AUTOSAR XML (schema 4-2-1)
package /MICROSAR/ComM_swc
  mode declaration group ComMMode: initial-mode=COMM_NO_COMMUNICATION
    mode COMM_NO_COMMUNICATION
    mode COMM_SILENT_COMMUNICATION
    mode COMM_FULL_COMMUNICATION
  data type mapping set ComMMode_DataTypeMappingSet: mode-request-type-map{implementation-data-type=ComM_ModeType, mode-group=ComMMode}  # Data Mapping for the Mode Declaration Group ComMMode.
package /MICROSAR/ComM_swc/DataTypes
  4 x impl type, all with category=TYPE_REFERENCE, implementation-data-type=uint8:
    ComM_ModeType: compu {0=COMM_NO_COMMUNICATION, 1=COMM_SILENT_COMMUNICATION, 2=COMM_FULL_COMMUNICATION}, range raw 0..3
    ComM_InhibitionStatusType: range raw 0..255
    ComM_UserHandleType: range raw 0..255
    NetworkHandleType: range raw 0..255, type-emitter=ComM
package /MICROSAR/ComM_swc/Interfaces
  4 x client server interface, all with is-service=true, service-kind=COM-MANAGER:
    ComM_UserRequest
      4 x operation:
        RequestComMode: possible-error=[ComM_UserRequest/E_NOT_OK, E_MODE_LIMITATION]
          arg ComMode: type=ComM_ModeType, direction=IN
        GetCurrentComMode: possible-error=ComM_UserRequest/E_NOT_OK
          arg ComMode: type=ComM_ModeType, direction=OUT
        GetMaxComMode: possible-error=ComM_UserRequest/E_NOT_OK
          arg ComMode: type=ComM_ModeType, direction=OUT
        GetRequestedComMode: possible-error=ComM_UserRequest/E_NOT_OK
          arg ComMode: type=ComM_ModeType, direction=OUT
      error E_NOT_OK: error-code=1
      error E_MODE_LIMITATION: error-code=2
    ComM_ECUModeLimitation
      4 x operation, all with possible-error=ComM_ECUModeLimitation/E_NOT_OK:
        LimitECUToNoComMode
          arg Status: type=boolean, direction=IN
        ReadInhibitCounter
          arg CounterValue: type=uint16, direction=OUT
        ResetInhibitCounter
        SetECUGroupClassification
          arg Status: type=ComM_InhibitionStatusType, direction=IN
      error E_NOT_OK: error-code=1
    ComM_ChannelWakeUp
      operation PreventWakeUp: possible-error=ComM_ChannelWakeUp/E_NOT_OK
        arg Status: type=boolean, direction=IN
      operation GetInhibitionStatus: possible-error=ComM_ChannelWakeUp/E_NOT_OK
        arg Status: type=ComM_InhibitionStatusType, direction=OUT
      error E_NOT_OK: error-code=1
    ComM_ChannelLimitation
      operation LimitChannelToNoComMode: possible-error=ComM_ChannelLimitation/E_NOT_OK
        arg Status: type=boolean, direction=IN
      operation GetInhibitionStatus: possible-error=ComM_ChannelLimitation/E_NOT_OK
        arg Status: type=ComM_InhibitionStatusType, direction=OUT
      error E_NOT_OK: error-code=1
  mode switch interface ComM_CurrentMode: is-service=true, service-kind=COM-MANAGER
    mode group currentMode: type=ComMMode
package /MICROSAR/ComM_swc/ComponentTypes
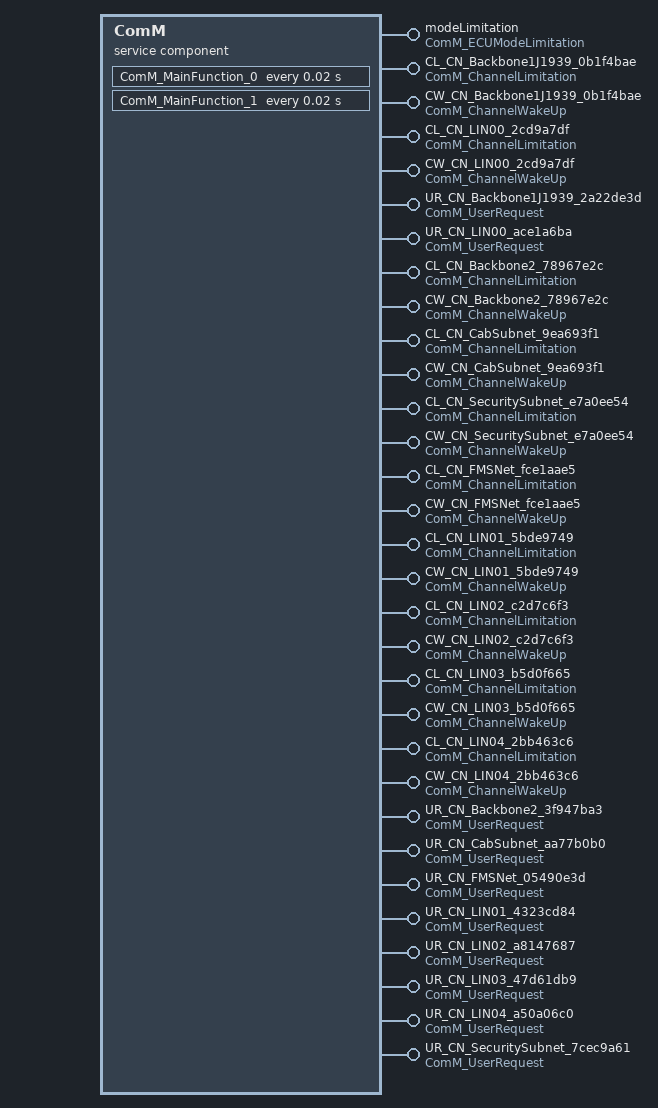
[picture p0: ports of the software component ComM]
  service sw component type ComM: category=SERVICE_COMPONENT
    31 x provide port:
      modeLimitation: provided-interface=ComM_ECUModeLimitation
      CL_CN_Backbone1J1939_0b1f4bae: provided-interface=ComM_ChannelLimitation
      CW_CN_Backbone1J1939_0b1f4bae: provided-interface=ComM_ChannelWakeUp
      CL_CN_LIN00_2cd9a7df: provided-interface=ComM_ChannelLimitation
      CW_CN_LIN00_2cd9a7df: provided-interface=ComM_ChannelWakeUp
      UR_CN_Backbone1J1939_2a22de3d: provided-interface=ComM_UserRequest
      UR_CN_LIN00_ace1a6ba: provided-interface=ComM_UserRequest
      CL_CN_Backbone2_78967e2c: provided-interface=ComM_ChannelLimitation
      CW_CN_Backbone2_78967e2c: provided-interface=ComM_ChannelWakeUp
      CL_CN_CabSubnet_9ea693f1: provided-interface=ComM_ChannelLimitation
      CW_CN_CabSubnet_9ea693f1: provided-interface=ComM_ChannelWakeUp
      CL_CN_SecuritySubnet_e7a0ee54: provided-interface=ComM_ChannelLimitation
      CW_CN_SecuritySubnet_e7a0ee54: provided-interface=ComM_ChannelWakeUp
      CL_CN_FMSNet_fce1aae5: provided-interface=ComM_ChannelLimitation
      CW_CN_FMSNet_fce1aae5: provided-interface=ComM_ChannelWakeUp
      CL_CN_LIN01_5bde9749: provided-interface=ComM_ChannelLimitation
      CW_CN_LIN01_5bde9749: provided-interface=ComM_ChannelWakeUp
      CL_CN_LIN02_c2d7c6f3: provided-interface=ComM_ChannelLimitation
      CW_CN_LIN02_c2d7c6f3: provided-interface=ComM_ChannelWakeUp
      CL_CN_LIN03_b5d0f665: provided-interface=ComM_ChannelLimitation
      CW_CN_LIN03_b5d0f665: provided-interface=ComM_ChannelWakeUp
      CL_CN_LIN04_2bb463c6: provided-interface=ComM_ChannelLimitation
      CW_CN_LIN04_2bb463c6: provided-interface=ComM_ChannelWakeUp
      UR_CN_Backbone2_3f947ba3: provided-interface=ComM_UserRequest
      UR_CN_CabSubnet_aa77b0b0: provided-interface=ComM_UserRequest
      UR_CN_FMSNet_05490e3d: provided-interface=ComM_UserRequest
      UR_CN_LIN01_4323cd84: provided-interface=ComM_UserRequest
      UR_CN_LIN02_a8147687: provided-interface=ComM_UserRequest
      UR_CN_LIN03_47d61db9: provided-interface=ComM_UserRequest
      UR_CN_LIN04_a50a06c0: provided-interface=ComM_UserRequest
      UR_CN_SecuritySubnet_7cec9a61: provided-interface=ComM_UserRequest
    behavior ComMInternalBehavior: data-type-mapping=ComMMode_DataTypeMappingSet, handle-termination-and-restart=NO-SUPPORT, included-data-type-set=data-type=[ComM_ModeType, ComM_InhibitionStatusType, ComM_UserHandleType, NetworkHandleType]
      timing event Timer_ComM_MainFunction_0: start-on-event=ComM_MainFunction_0, period=0.02
      timing event Timer_ComM_MainFunction_1: start-on-event=ComM_MainFunction_1, period=0.02
      20 x operation invoked event:
        OpEventGetInhibitionStatus_GetInhibitionStatus_CL_CN_Backbone1J1939_0b1f4bae: start-on-event=GetInhibitionStatus, operation=CL_CN_Backbone1J1939_0b1f4bae.GetInhibitionStatus
        OpEventGetInhibitionStatus_GetInhibitionStatus_CW_CN_Backbone1J1939_0b1f4bae: start-on-event=GetInhibitionStatus, operation=CW_CN_Backbone1J1939_0b1f4bae.GetInhibitionStatus
        OpEventGetInhibitionStatus_GetInhibitionStatus_CL_CN_LIN00_2cd9a7df: start-on-event=GetInhibitionStatus, operation=CL_CN_LIN00_2cd9a7df.GetInhibitionStatus
        OpEventGetInhibitionStatus_GetInhibitionStatus_CW_CN_LIN00_2cd9a7df: start-on-event=GetInhibitionStatus, operation=CW_CN_LIN00_2cd9a7df.GetInhibitionStatus
        OpEventLimitECUToNoComMode_LimitECUToNoComMode_modeLimitation: start-on-event=LimitECUToNoComMode, operation=modeLimitation.LimitECUToNoComMode
        OpEventReadInhibitCounter_ReadInhibitCounter_modeLimitation: start-on-event=ReadInhibitCounter, operation=modeLimitation.ReadInhibitCounter
        OpEventResetInhibitCounter_ResetInhibitCounter_modeLimitation: start-on-event=ResetInhibitCounter, operation=modeLimitation.ResetInhibitCounter
        OpEventSetECUGroupClassification_SetECUGroupClassification_modeLimitation: start-on-event=SetECUGroupClassification, operation=modeLimitation.SetECUGroupClassification
        OpEventLimitChannelToNoComMode_LimitChannelToNoComMode_CL_CN_Backbone1J1939_0b1f4bae: start-on-event=LimitChannelToNoComMode, operation=CL_CN_Backbone1J1939_0b1f4bae.LimitChannelToNoComMode
        OpEventLimitChannelToNoComMode_LimitChannelToNoComMode_CL_CN_LIN00_2cd9a7df: start-on-event=LimitChannelToNoComMode, operation=CL_CN_LIN00_2cd9a7df.LimitChannelToNoComMode
        OpEventPreventWakeUp_PreventWakeUp_CW_CN_Backbone1J1939_0b1f4bae: start-on-event=PreventWakeUp, operation=CW_CN_Backbone1J1939_0b1f4bae.PreventWakeUp
        OpEventPreventWakeUp_PreventWakeUp_CW_CN_LIN00_2cd9a7df: start-on-event=PreventWakeUp, operation=CW_CN_LIN00_2cd9a7df.PreventWakeUp
        OpEventRequestComMode_RequestComMode_UR_CN_Backbone1J1939_2a22de3d: start-on-event=RequestComMode, operation=UR_CN_Backbone1J1939_2a22de3d.RequestComMode
        OpEventRequestComMode_RequestComMode_UR_CN_LIN00_ace1a6ba: start-on-event=RequestComMode, operation=UR_CN_LIN00_ace1a6ba.RequestComMode
        OpEventGetCurrentComMode_GetCurrentComMode_UR_CN_Backbone1J1939_2a22de3d: start-on-event=GetCurrentComMode, operation=UR_CN_Backbone1J1939_2a22de3d.GetCurrentComMode
        OpEventGetCurrentComMode_GetCurrentComMode_UR_CN_LIN00_ace1a6ba: start-on-event=GetCurrentComMode, operation=UR_CN_LIN00_ace1a6ba.GetCurrentComMode
        OpEventGetMaxComMode_GetMaxComMode_UR_CN_Backbone1J1939_2a22de3d: start-on-event=GetMaxComMode, operation=UR_CN_Backbone1J1939_2a22de3d.GetMaxComMode
        OpEventGetMaxComMode_GetMaxComMode_UR_CN_LIN00_ace1a6ba: start-on-event=GetMaxComMode, operation=UR_CN_LIN00_ace1a6ba.GetMaxComMode
        OpEventGetRequestedComMode_GetRequestedComMode_UR_CN_Backbone1J1939_2a22de3d: start-on-event=GetRequestedComMode, operation=UR_CN_Backbone1J1939_2a22de3d.GetRequestedComMode
        OpEventGetRequestedComMode_GetRequestedComMode_UR_CN_LIN00_ace1a6ba: start-on-event=GetRequestedComMode, operation=UR_CN_LIN00_ace1a6ba.GetRequestedComMode
      8 x timing event, all with period=0.02:
        Timer_ComM_MainFunction_{2..9}: start-on-event=ComM_MainFunction_{2..9}
      64 x operation invoked event:
        OpEventGetInhibitionStatus_GetInhibitionStatus_CL_CN_Backbone2_78967e2c: start-on-event=GetInhibitionStatus, operation=CL_CN_Backbone2_78967e2c.GetInhibitionStatus
        OpEventGetInhibitionStatus_GetInhibitionStatus_CW_CN_Backbone2_78967e2c: start-on-event=GetInhibitionStatus, operation=CW_CN_Backbone2_78967e2c.GetInhibitionStatus
        OpEventGetInhibitionStatus_GetInhibitionStatus_CL_CN_CabSubnet_9ea693f1: start-on-event=GetInhibitionStatus, operation=CL_CN_CabSubnet_9ea693f1.GetInhibitionStatus
        OpEventGetInhibitionStatus_GetInhibitionStatus_CW_CN_CabSubnet_9ea693f1: start-on-event=GetInhibitionStatus, operation=CW_CN_CabSubnet_9ea693f1.GetInhibitionStatus
        OpEventGetInhibitionStatus_GetInhibitionStatus_CL_CN_SecuritySubnet_e7a0ee54: start-on-event=GetInhibitionStatus, operation=CL_CN_SecuritySubnet_e7a0ee54.GetInhibitionStatus
        OpEventGetInhibitionStatus_GetInhibitionStatus_CW_CN_SecuritySubnet_e7a0ee54: start-on-event=GetInhibitionStatus, operation=CW_CN_SecuritySubnet_e7a0ee54.GetInhibitionStatus
        OpEventGetInhibitionStatus_GetInhibitionStatus_CL_CN_FMSNet_fce1aae5: start-on-event=GetInhibitionStatus, operation=CL_CN_FMSNet_fce1aae5.GetInhibitionStatus
        OpEventGetInhibitionStatus_GetInhibitionStatus_CW_CN_FMSNet_fce1aae5: start-on-event=GetInhibitionStatus, operation=CW_CN_FMSNet_fce1aae5.GetInhibitionStatus
        OpEventGetInhibitionStatus_GetInhibitionStatus_CL_CN_LIN01_5bde9749: start-on-event=GetInhibitionStatus, operation=CL_CN_LIN01_5bde9749.GetInhibitionStatus
        OpEventGetInhibitionStatus_GetInhibitionStatus_CW_CN_LIN01_5bde9749: start-on-event=GetInhibitionStatus, operation=CW_CN_LIN01_5bde9749.GetInhibitionStatus
        OpEventGetInhibitionStatus_GetInhibitionStatus_CL_CN_LIN02_c2d7c6f3: start-on-event=GetInhibitionStatus, operation=CL_CN_LIN02_c2d7c6f3.GetInhibitionStatus
        OpEventGetInhibitionStatus_GetInhibitionStatus_CW_CN_LIN02_c2d7c6f3: start-on-event=GetInhibitionStatus, operation=CW_CN_LIN02_c2d7c6f3.GetInhibitionStatus
        OpEventGetInhibitionStatus_GetInhibitionStatus_CL_CN_LIN03_b5d0f665: start-on-event=GetInhibitionStatus, operation=CL_CN_LIN03_b5d0f665.GetInhibitionStatus
        OpEventGetInhibitionStatus_GetInhibitionStatus_CW_CN_LIN03_b5d0f665: start-on-event=GetInhibitionStatus, operation=CW_CN_LIN03_b5d0f665.GetInhibitionStatus
        OpEventGetInhibitionStatus_GetInhibitionStatus_CL_CN_LIN04_2bb463c6: start-on-event=GetInhibitionStatus, operation=CL_CN_LIN04_2bb463c6.GetInhibitionStatus
        OpEventGetInhibitionStatus_GetInhibitionStatus_CW_CN_LIN04_2bb463c6: start-on-event=GetInhibitionStatus, operation=CW_CN_LIN04_2bb463c6.GetInhibitionStatus
        OpEventLimitChannelToNoComMode_LimitChannelToNoComMode_CL_CN_Backbone2_78967e2c: start-on-event=LimitChannelToNoComMode, operation=CL_CN_Backbone2_78967e2c.LimitChannelToNoComMode
        OpEventLimitChannelToNoComMode_LimitChannelToNoComMode_CL_CN_CabSubnet_9ea693f1: start-on-event=LimitChannelToNoComMode, operation=CL_CN_CabSubnet_9ea693f1.LimitChannelToNoComMode
        OpEventLimitChannelToNoComMode_LimitChannelToNoComMode_CL_CN_SecuritySubnet_e7a0ee54: start-on-event=LimitChannelToNoComMode, operation=CL_CN_SecuritySubnet_e7a0ee54.LimitChannelToNoComMode
        OpEventLimitChannelToNoComMode_LimitChannelToNoComMode_CL_CN_FMSNet_fce1aae5: start-on-event=LimitChannelToNoComMode, operation=CL_CN_FMSNet_fce1aae5.LimitChannelToNoComMode
        OpEventLimitChannelToNoComMode_LimitChannelToNoComMode_CL_CN_LIN01_5bde9749: start-on-event=LimitChannelToNoComMode, operation=CL_CN_LIN01_5bde9749.LimitChannelToNoComMode
        OpEventLimitChannelToNoComMode_LimitChannelToNoComMode_CL_CN_LIN02_c2d7c6f3: start-on-event=LimitChannelToNoComMode, operation=CL_CN_LIN02_c2d7c6f3.LimitChannelToNoComMode
        OpEventLimitChannelToNoComMode_LimitChannelToNoComMode_CL_CN_LIN03_b5d0f665: start-on-event=LimitChannelToNoComMode, operation=CL_CN_LIN03_b5d0f665.LimitChannelToNoComMode
        OpEventLimitChannelToNoComMode_LimitChannelToNoComMode_CL_CN_LIN04_2bb463c6: start-on-event=LimitChannelToNoComMode, operation=CL_CN_LIN04_2bb463c6.LimitChannelToNoComMode
        OpEventPreventWakeUp_PreventWakeUp_CW_CN_Backbone2_78967e2c: start-on-event=PreventWakeUp, operation=CW_CN_Backbone2_78967e2c.PreventWakeUp
        OpEventPreventWakeUp_PreventWakeUp_CW_CN_CabSubnet_9ea693f1: start-on-event=PreventWakeUp, operation=CW_CN_CabSubnet_9ea693f1.PreventWakeUp
        OpEventPreventWakeUp_PreventWakeUp_CW_CN_SecuritySubnet_e7a0ee54: start-on-event=PreventWakeUp, operation=CW_CN_SecuritySubnet_e7a0ee54.PreventWakeUp
        OpEventPreventWakeUp_PreventWakeUp_CW_CN_FMSNet_fce1aae5: start-on-event=PreventWakeUp, operation=CW_CN_FMSNet_fce1aae5.PreventWakeUp
        OpEventPreventWakeUp_PreventWakeUp_CW_CN_LIN01_5bde9749: start-on-event=PreventWakeUp, operation=CW_CN_LIN01_5bde9749.PreventWakeUp
        OpEventPreventWakeUp_PreventWakeUp_CW_CN_LIN02_c2d7c6f3: start-on-event=PreventWakeUp, operation=CW_CN_LIN02_c2d7c6f3.PreventWakeUp
        OpEventPreventWakeUp_PreventWakeUp_CW_CN_LIN03_b5d0f665: start-on-event=PreventWakeUp, operation=CW_CN_LIN03_b5d0f665.PreventWakeUp
        OpEventPreventWakeUp_PreventWakeUp_CW_CN_LIN04_2bb463c6: start-on-event=PreventWakeUp, operation=CW_CN_LIN04_2bb463c6.PreventWakeUp
        OpEventRequestComMode_RequestComMode_UR_CN_Backbone2_3f947ba3: start-on-event=RequestComMode, operation=UR_CN_Backbone2_3f947ba3.RequestComMode
        OpEventRequestComMode_RequestComMode_UR_CN_CabSubnet_aa77b0b0: start-on-event=RequestComMode, operation=UR_CN_CabSubnet_aa77b0b0.RequestComMode
        OpEventRequestComMode_RequestComMode_UR_CN_FMSNet_05490e3d: start-on-event=RequestComMode, operation=UR_CN_FMSNet_05490e3d.RequestComMode
        OpEventRequestComMode_RequestComMode_UR_CN_LIN01_4323cd84: start-on-event=RequestComMode, operation=UR_CN_LIN01_4323cd84.RequestComMode
        OpEventRequestComMode_RequestComMode_UR_CN_LIN02_a8147687: start-on-event=RequestComMode, operation=UR_CN_LIN02_a8147687.RequestComMode
        OpEventRequestComMode_RequestComMode_UR_CN_LIN03_47d61db9: start-on-event=RequestComMode, operation=UR_CN_LIN03_47d61db9.RequestComMode
        OpEventRequestComMode_RequestComMode_UR_CN_LIN04_a50a06c0: start-on-event=RequestComMode, operation=UR_CN_LIN04_a50a06c0.RequestComMode
        OpEventRequestComMode_RequestComMode_UR_CN_SecuritySubnet_7cec9a61: start-on-event=RequestComMode, operation=UR_CN_SecuritySubnet_7cec9a61.RequestComMode
        OpEventGetCurrentComMode_GetCurrentComMode_UR_CN_Backbone2_3f947ba3: start-on-event=GetCurrentComMode, operation=UR_CN_Backbone2_3f947ba3.GetCurrentComMode
        OpEventGetCurrentComMode_GetCurrentComMode_UR_CN_CabSubnet_aa77b0b0: start-on-event=GetCurrentComMode, operation=UR_CN_CabSubnet_aa77b0b0.GetCurrentComMode
        OpEventGetCurrentComMode_GetCurrentComMode_UR_CN_FMSNet_05490e3d: start-on-event=GetCurrentComMode, operation=UR_CN_FMSNet_05490e3d.GetCurrentComMode
        OpEventGetCurrentComMode_GetCurrentComMode_UR_CN_LIN01_4323cd84: start-on-event=GetCurrentComMode, operation=UR_CN_LIN01_4323cd84.GetCurrentComMode
        OpEventGetCurrentComMode_GetCurrentComMode_UR_CN_LIN02_a8147687: start-on-event=GetCurrentComMode, operation=UR_CN_LIN02_a8147687.GetCurrentComMode
        OpEventGetCurrentComMode_GetCurrentComMode_UR_CN_LIN03_47d61db9: start-on-event=GetCurrentComMode, operation=UR_CN_LIN03_47d61db9.GetCurrentComMode
        OpEventGetCurrentComMode_GetCurrentComMode_UR_CN_LIN04_a50a06c0: start-on-event=GetCurrentComMode, operation=UR_CN_LIN04_a50a06c0.GetCurrentComMode
        OpEventGetCurrentComMode_GetCurrentComMode_UR_CN_SecuritySubnet_7cec9a61: start-on-event=GetCurrentComMode, operation=UR_CN_SecuritySubnet_7cec9a61.GetCurrentComMode
        OpEventGetMaxComMode_GetMaxComMode_UR_CN_Backbone2_3f947ba3: start-on-event=GetMaxComMode, operation=UR_CN_Backbone2_3f947ba3.GetMaxComMode
        OpEventGetMaxComMode_GetMaxComMode_UR_CN_CabSubnet_aa77b0b0: start-on-event=GetMaxComMode, operation=UR_CN_CabSubnet_aa77b0b0.GetMaxComMode
        OpEventGetMaxComMode_GetMaxComMode_UR_CN_FMSNet_05490e3d: start-on-event=GetMaxComMode, operation=UR_CN_FMSNet_05490e3d.GetMaxComMode
        OpEventGetMaxComMode_GetMaxComMode_UR_CN_LIN01_4323cd84: start-on-event=GetMaxComMode, operation=UR_CN_LIN01_4323cd84.GetMaxComMode
        OpEventGetMaxComMode_GetMaxComMode_UR_CN_LIN02_a8147687: start-on-event=GetMaxComMode, operation=UR_CN_LIN02_a8147687.GetMaxComMode
        OpEventGetMaxComMode_GetMaxComMode_UR_CN_LIN03_47d61db9: start-on-event=GetMaxComMode, operation=UR_CN_LIN03_47d61db9.GetMaxComMode
        OpEventGetMaxComMode_GetMaxComMode_UR_CN_LIN04_a50a06c0: start-on-event=GetMaxComMode, operation=UR_CN_LIN04_a50a06c0.GetMaxComMode
        OpEventGetMaxComMode_GetMaxComMode_UR_CN_SecuritySubnet_7cec9a61: start-on-event=GetMaxComMode, operation=UR_CN_SecuritySubnet_7cec9a61.GetMaxComMode
        OpEventGetRequestedComMode_GetRequestedComMode_UR_CN_Backbone2_3f947ba3: start-on-event=GetRequestedComMode, operation=UR_CN_Backbone2_3f947ba3.GetRequestedComMode
        OpEventGetRequestedComMode_GetRequestedComMode_UR_CN_CabSubnet_aa77b0b0: start-on-event=GetRequestedComMode, operation=UR_CN_CabSubnet_aa77b0b0.GetRequestedComMode
        OpEventGetRequestedComMode_GetRequestedComMode_UR_CN_FMSNet_05490e3d: start-on-event=GetRequestedComMode, operation=UR_CN_FMSNet_05490e3d.GetRequestedComMode
        OpEventGetRequestedComMode_GetRequestedComMode_UR_CN_LIN01_4323cd84: start-on-event=GetRequestedComMode, operation=UR_CN_LIN01_4323cd84.GetRequestedComMode
        OpEventGetRequestedComMode_GetRequestedComMode_UR_CN_LIN02_a8147687: start-on-event=GetRequestedComMode, operation=UR_CN_LIN02_a8147687.GetRequestedComMode
        OpEventGetRequestedComMode_GetRequestedComMode_UR_CN_LIN03_47d61db9: start-on-event=GetRequestedComMode, operation=UR_CN_LIN03_47d61db9.GetRequestedComMode
        OpEventGetRequestedComMode_GetRequestedComMode_UR_CN_LIN04_a50a06c0: start-on-event=GetRequestedComMode, operation=UR_CN_LIN04_a50a06c0.GetRequestedComMode
        OpEventGetRequestedComMode_GetRequestedComMode_UR_CN_SecuritySubnet_7cec9a61: start-on-event=GetRequestedComMode, operation=UR_CN_SecuritySubnet_7cec9a61.GetRequestedComMode
      port-api-options:
        enable-take-address=true, indirect-api=false, port=modeLimitation
        {enable-take-address=true, indirect-api=false, port-defined-argument-value{value=0, value-type=NetworkHandleType}, port=CL_CN_Backbone2_78967e2c}
        {enable-take-address=true, indirect-api=false, port-defined-argument-value{value=0, value-type=NetworkHandleType}, port=CW_CN_Backbone2_78967e2c}
        {enable-take-address=true, indirect-api=false, port-defined-argument-value{value=1, value-type=NetworkHandleType}, port=CL_CN_CabSubnet_9ea693f1}
        {enable-take-address=true, indirect-api=false, port-defined-argument-value{value=1, value-type=NetworkHandleType}, port=CW_CN_CabSubnet_9ea693f1}
        {enable-take-address=true, indirect-api=false, port-defined-argument-value{value=2, value-type=NetworkHandleType}, port=CL_CN_SecuritySubnet_e7a0ee54}
        {enable-take-address=true, indirect-api=false, port-defined-argument-value{value=2, value-type=NetworkHandleType}, port=CW_CN_SecuritySubnet_e7a0ee54}
        {enable-take-address=true, indirect-api=false, port-defined-argument-value{value=3, value-type=NetworkHandleType}, port=CL_CN_Backbone1J1939_0b1f4bae}
        {enable-take-address=true, indirect-api=false, port-defined-argument-value{value=3, value-type=NetworkHandleType}, port=CW_CN_Backbone1J1939_0b1f4bae}
        {enable-take-address=true, indirect-api=false, port-defined-argument-value{value=4, value-type=NetworkHandleType}, port=CL_CN_FMSNet_fce1aae5}
        {enable-take-address=true, indirect-api=false, port-defined-argument-value{value=4, value-type=NetworkHandleType}, port=CW_CN_FMSNet_fce1aae5}
        {enable-take-address=true, indirect-api=false, port-defined-argument-value{value=5, value-type=NetworkHandleType}, port=CL_CN_LIN00_2cd9a7df}
        {enable-take-address=true, indirect-api=false, port-defined-argument-value{value=5, value-type=NetworkHandleType}, port=CW_CN_LIN00_2cd9a7df}
        {enable-take-address=true, indirect-api=false, port-defined-argument-value{value=6, value-type=NetworkHandleType}, port=CL_CN_LIN01_5bde9749}
        {enable-take-address=true, indirect-api=false, port-defined-argument-value{value=6, value-type=NetworkHandleType}, port=CW_CN_LIN01_5bde9749}
        {enable-take-address=true, indirect-api=false, port-defined-argument-value{value=7, value-type=NetworkHandleType}, port=CL_CN_LIN02_c2d7c6f3}
        {enable-take-address=true, indirect-api=false, port-defined-argument-value{value=7, value-type=NetworkHandleType}, port=CW_CN_LIN02_c2d7c6f3}
        {enable-take-address=true, indirect-api=false, port-defined-argument-value{value=8, value-type=NetworkHandleType}, port=CL_CN_LIN03_b5d0f665}
        {enable-take-address=true, indirect-api=false, port-defined-argument-value{value=8, value-type=NetworkHandleType}, port=CW_CN_LIN03_b5d0f665}
        {enable-take-address=true, indirect-api=false, port-defined-argument-value{value=9, value-type=NetworkHandleType}, port=CL_CN_LIN04_2bb463c6}
        {enable-take-address=true, indirect-api=false, port-defined-argument-value{value=9, value-type=NetworkHandleType}, port=CW_CN_LIN04_2bb463c6}
        {enable-take-address=true, indirect-api=false, port-defined-argument-value{value=3, value-type=ComM_UserHandleType}, port=UR_CN_Backbone1J1939_2a22de3d}
        {enable-take-address=true, indirect-api=false, port-defined-argument-value{value=0, value-type=ComM_UserHandleType}, port=UR_CN_Backbone2_3f947ba3}
        {enable-take-address=true, indirect-api=false, port-defined-argument-value{value=1, value-type=ComM_UserHandleType}, port=UR_CN_CabSubnet_aa77b0b0}
        {enable-take-address=true, indirect-api=false, port-defined-argument-value{value=4, value-type=ComM_UserHandleType}, port=UR_CN_FMSNet_05490e3d}
        {enable-take-address=true, indirect-api=false, port-defined-argument-value{value=5, value-type=ComM_UserHandleType}, port=UR_CN_LIN00_ace1a6ba}
        {enable-take-address=true, indirect-api=false, port-defined-argument-value{value=6, value-type=ComM_UserHandleType}, port=UR_CN_LIN01_4323cd84}
        {enable-take-address=true, indirect-api=false, port-defined-argument-value{value=7, value-type=ComM_UserHandleType}, port=UR_CN_LIN02_a8147687}
        {enable-take-address=true, indirect-api=false, port-defined-argument-value{value=8, value-type=ComM_UserHandleType}, port=UR_CN_LIN03_47d61db9}
        {enable-take-address=true, indirect-api=false, port-defined-argument-value{value=9, value-type=ComM_UserHandleType}, port=UR_CN_LIN04_a50a06c0}
        {enable-take-address=true, indirect-api=false, port-defined-argument-value{value=2, value-type=ComM_UserHandleType}, port=UR_CN_SecuritySubnet_7cec9a61}
      21 x runnable, all with can-be-invoked-concurrently=true:
        ComM_MainFunction_0
        ComM_MainFunction_1
        GetInhibitionStatus: symbol=ComM_GetInhibitionStatus
        LimitECUToNoComMode: symbol=ComM_LimitECUToNoComMode
        ReadInhibitCounter: symbol=ComM_ReadInhibitCounter
        ResetInhibitCounter: symbol=ComM_ResetInhibitCounter
        SetECUGroupClassification: symbol=ComM_SetECUGroupClassification
        LimitChannelToNoComMode: symbol=ComM_LimitChannelToNoComMode
        PreventWakeUp: symbol=ComM_PreventWakeUp
        RequestComMode: symbol=ComM_RequestComMode
        GetCurrentComMode: symbol=ComM_GetCurrentComMode
        GetMaxComMode: symbol=ComM_GetMaxComMode
        GetRequestedComMode: symbol=ComM_GetRequestedComMode
        ComM_MainFunction_{2..9}
  swc implementation ComMImplementation: programming-language=C, behavior=ComMInternalBehavior
